# BlockC: IP-XACT component
VLNV example.org:FutureLib:BlockC:1.0

## Address spaces and blocks
BlockCMap.BlockCRegs: base 0x0000, range 0x100, width 32

## Registers
Registers are 32-bit, read-write, no defined reset value unless marked. A register's access mark holds for its fields unless they carry their own. Offsets are from the block's base; lines under a group give offsets from that group; [hi:lo] are bit positions; {n}, {i} and the like mark numbered series; 'fields as' and 'values as' point back to an identical list; <NAME> marks a mode.

## BlockCMap.BlockCRegs
Base 0x00000000
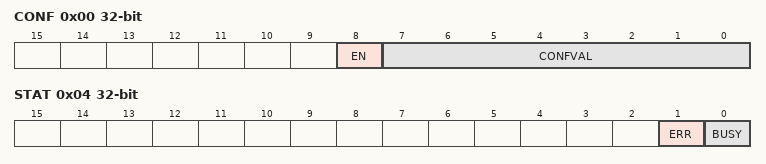
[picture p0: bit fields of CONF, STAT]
0x00 CONF
  [8] EN, [7:0] CONFVAL
0x04 STAT ro
  [1] ERR, [0] BUSY
0x08 DATAIN wo
  [31:0] IN
0x0C DATAOUT ro
  [31:0] OUT
0x10 CFG2
  [15:0] CFGVAL2
